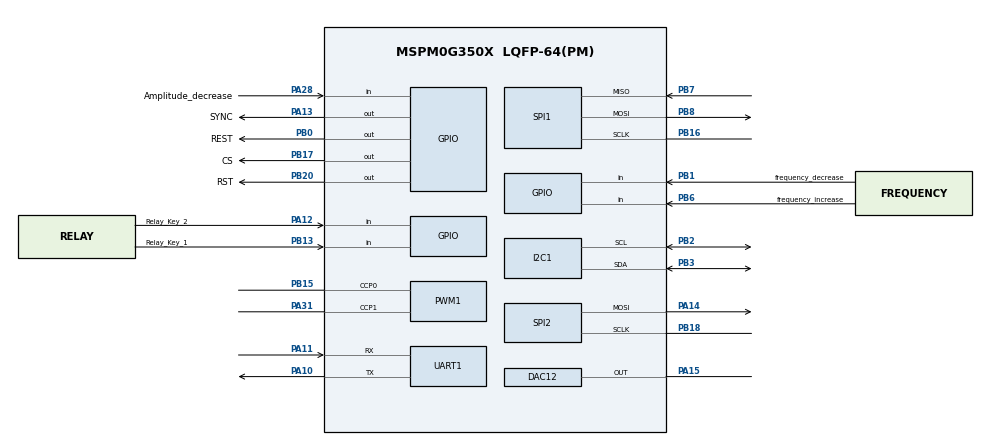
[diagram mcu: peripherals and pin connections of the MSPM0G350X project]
/**
 * @cliArgs --device "MSPM0G350X" --part "Default" --package "LQFP-64(PM)" --product "mspm0_sdk@2.04.00.06"
 * @versions {"tool":"1.24.0+4110"}
 */

/**
 * Import the modules used in this configuration.
 */
const DAC12         = scripting.addModule("/ti/driverlib/DAC12");
const GPIO          = scripting.addModule("/ti/driverlib/GPIO", {}, false);
const GPIO1         = GPIO.addInstance();
const GPIO2         = GPIO.addInstance();
const GPIO3         = GPIO.addInstance();
const GPIO4         = GPIO.addInstance();
const I2C           = scripting.addModule("/ti/driverlib/I2C", {}, false);
const I2C1          = I2C.addInstance();
const MATHACL       = scripting.addModule("/ti/driverlib/MATHACL");
const PWM           = scripting.addModule("/ti/driverlib/PWM", {}, false);
const PWM1          = PWM.addInstance();
const SPI           = scripting.addModule("/ti/driverlib/SPI", {}, false);
const SPI1          = SPI.addInstance();
const SPI2          = SPI.addInstance();
const SYSCTL        = scripting.addModule("/ti/driverlib/SYSCTL");
const SYSTICK       = scripting.addModule("/ti/driverlib/SYSTICK");
const UART          = scripting.addModule("/ti/driverlib/UART", {}, false);
const UART1         = UART.addInstance();
const ProjectConfig = scripting.addModule("/ti/project_config/ProjectConfig");

/**
 * Write custom configuration values to the imported modules.
 */
const divider6       = system.clockTree["PLL_CLK2X_DIV"];
divider6.divideValue = 4;

const divider7       = system.clockTree["PLL_PDIV"];
divider7.divideValue = 2;

const gate8  = system.clockTree["MFPCLKGATE"];
gate8.enable = true;

const multiplier2         = system.clockTree["PLL_QDIV"];
multiplier2.multiplyValue = 10;

const mux10       = system.clockTree["MFPCLKMUX"];
mux10.inputSelect = "MFPCLKMUX_HFCLK";

DAC12.dacOutputPinEn            = true;
DAC12.dacAmplifier              = "ON";
DAC12.dacSampleTimerEn          = true;
DAC12.dacNegVREF                = "VEREFN";
DAC12.peripheral.$assign        = "DAC0";
DAC12.peripheral.OutPin.$assign = "PA15";
DAC12.OutPinConfig.$name        = "ti_driverlib_gpio_GPIOPinGeneric5";
DAC12.OutPinConfig.enableConfig = true;

const Board = scripting.addModule("/ti/driverlib/Board", {}, false);

GPIO1.port                          = "PORTB";
GPIO1.$name                         = "GPIO_LEDS";
GPIO1.associatedPins.create(3);
GPIO1.associatedPins[0].$name       = "USER_LED_1";
GPIO1.associatedPins[0].assignedPin = "22";
GPIO1.associatedPins[1].$name       = "USER_LED_2";
GPIO1.associatedPins[1].assignedPin = "26";
GPIO1.associatedPins[2].$name       = "USER_LED_3";
GPIO1.associatedPins[2].assignedPin = "27";

GPIO2.$name                              = "AD7606";
GPIO2.port                               = "PORTB";
GPIO2.associatedPins.create(3);
GPIO2.associatedPins[0].internalResistor = "PULL_UP";
GPIO2.associatedPins[0].interruptEn      = true;
GPIO2.associatedPins[0].direction        = "INPUT";
GPIO2.associatedPins[0].$name            = "Busy";
GPIO2.associatedPins[0].polarity         = "FALL";
GPIO2.associatedPins[0].assignedPin      = "4";
GPIO2.associatedPins[1].$name            = "REST";
GPIO2.associatedPins[1].internalResistor = "PULL_UP";
GPIO2.associatedPins[1].pin.$assign      = "PB0";
GPIO2.associatedPins[2].$name            = "CS";
GPIO2.associatedPins[2].internalResistor = "PULL_UP";
GPIO2.associatedPins[2].pin.$assign      = "PB17";

GPIO3.$name                              = "AD9834";
GPIO3.associatedPins.create(2);
GPIO3.associatedPins[0].$name            = "SYNC";
GPIO3.associatedPins[0].internalResistor = "PULL_UP";
GPIO3.associatedPins[0].ioStructure      = "HS";
GPIO3.associatedPins[0].pin.$assign      = "PA13";
GPIO3.associatedPins[1].$name            = "RST";
GPIO3.associatedPins[1].internalResistor = "PULL_UP";
GPIO3.associatedPins[1].pin.$assign      = "PB20";

GPIO4.$name                              = "GPIO_SWITCHES";
GPIO4.associatedPins.create(6);
GPIO4.associatedPins[0].direction        = "INPUT";
GPIO4.associatedPins[0].internalResistor = "PULL_UP";
GPIO4.associatedPins[0].interruptEn      = true;
GPIO4.associatedPins[0].$name            = "frequency_increase";
GPIO4.associatedPins[0].polarity         = "RISE_FALL";
GPIO4.associatedPins[0].pin.$assign      = "PB6";
GPIO4.associatedPins[1].internalResistor = "PULL_UP";
GPIO4.associatedPins[1].direction        = "INPUT";
GPIO4.associatedPins[1].interruptEn      = true;
GPIO4.associatedPins[1].$name            = "frequency_decrease";
GPIO4.associatedPins[1].polarity         = "RISE_FALL";
GPIO4.associatedPins[1].pin.$assign      = "PB1";
GPIO4.associatedPins[2].initialValue     = "SET";
GPIO4.associatedPins[2].direction        = "INPUT";
GPIO4.associatedPins[2].polarity         = "RISE_FALL";
GPIO4.associatedPins[2].interruptEn      = true;
GPIO4.associatedPins[2].$name            = "Amplitude_increase";
GPIO4.associatedPins[3].$name            = "Amplitude_decrease";
GPIO4.associatedPins[3].initialValue     = "SET";
GPIO4.associatedPins[3].direction        = "INPUT";
GPIO4.associatedPins[3].interruptEn      = true;
GPIO4.associatedPins[3].polarity         = "RISE_FALL";
GPIO4.associatedPins[3].pin.$assign      = "PA28";
GPIO4.associatedPins[4].$name            = "Relay_Key_1";
GPIO4.associatedPins[4].direction        = "INPUT";
GPIO4.associatedPins[4].interruptEn      = true;
GPIO4.associatedPins[4].polarity         = "RISE_FALL";
GPIO4.associatedPins[4].pin.$assign      = "PB13";
GPIO4.associatedPins[5].$name            = "Relay_Key_2";
GPIO4.associatedPins[5].direction        = "INPUT";
GPIO4.associatedPins[5].interruptEn      = true;
GPIO4.associatedPins[5].polarity         = "RISE_FALL";
GPIO4.associatedPins[5].pin.$assign      = "PA12";

I2C1.basicEnableController             = true;
I2C1.basicControllerStandardBusSpeed   = "Fast";
I2C1.$name                             = "I2C_1";
I2C1.peripheral.$assign                = "I2C1";
I2C1.peripheral.sdaPin.$assign         = "PB3";
I2C1.peripheral.sclPin.$assign         = "PB2";
I2C1.sdaPinConfig.$name                = "ti_driverlib_gpio_GPIOPinGeneric0";
I2C1.sdaPinConfig.hideOutputInversion  = scripting.forceWrite(false);
I2C1.sdaPinConfig.onlyInternalResistor = scripting.forceWrite(false);
I2C1.sdaPinConfig.passedPeripheralType = scripting.forceWrite("Digital");
I2C1.sclPinConfig.$name                = "ti_driverlib_gpio_GPIOPinGeneric1";
I2C1.sclPinConfig.hideOutputInversion  = scripting.forceWrite(false);
I2C1.sclPinConfig.onlyInternalResistor = scripting.forceWrite(false);
I2C1.sclPinConfig.passedPeripheralType = scripting.forceWrite("Digital");

PWM1.$name                      = "PWM_0";
PWM1.pwmMode                    = "EDGE_ALIGN_UP";
PWM1.clockPrescale              = 25;
PWM1.timerCount                 = 125;
PWM1.peripheral.ccp0Pin.$assign = "PB15";
PWM1.peripheral.ccp1Pin.$assign = "PA31";
PWM1.PWM_CHANNEL_0.$name        = "ti_driverlib_pwm_PWMTimerCC0";
PWM1.PWM_CHANNEL_0.dutyCycle    = 50;
PWM1.PWM_CHANNEL_1.$name        = "ti_driverlib_pwm_PWMTimerCC1";
PWM1.PWM_CHANNEL_1.dutyCycle    = 90;
PWM1.ccp0PinConfig.$name        = "ti_driverlib_gpio_GPIOPinGeneric8";
PWM1.ccp1PinConfig.$name        = "ti_driverlib_gpio_GPIOPinGeneric9";

SPI1.$name                          = "SPI_0";
SPI1.enabledDMAEvent1Triggers       = "DL_SPI_DMA_INTERRUPT_RX";
SPI1.enabledInterrupts              = ["DMA_DONE_RX"];
SPI1.targetBitRate                  = 16000000;
SPI1.txFifoThreshold                = "DL_SPI_TX_FIFO_LEVEL_EMPTY";
SPI1.dataSize                       = 16;
SPI1.rxFifoThreshold                = "DL_SPI_RX_FIFO_LEVEL_1_4_FULL";
SPI1.enabledDMAEvent2Triggers       = "DL_SPI_DMA_INTERRUPT_TX";
SPI1.frameFormat                    = "MOTO3";
SPI1.sclkPinConfig.$name            = "ti_driverlib_gpio_GPIOPinGeneric2";
SPI1.mosiPinConfig.$name            = "ti_driverlib_gpio_GPIOPinGeneric3";
SPI1.misoPinConfig.$name            = "ti_driverlib_gpio_GPIOPinGeneric4";
SPI1.DMA_CHANNEL_EVENT1.$name       = "DMA_CH0";
SPI1.DMA_CHANNEL_EVENT1.addressMode = "f2b";
SPI1.DMA_CHANNEL_EVENT1.srcLength   = "HALF_WORD";
SPI1.DMA_CHANNEL_EVENT1.dstLength   = "HALF_WORD";
SPI1.DMA_CHANNEL_EVENT2.$name       = "DMA_CH1";
SPI1.peripheral.$assign             = "SPI1";
SPI1.peripheral.sclkPin.$assign     = "PB16";
SPI1.peripheral.mosiPin.$assign     = "PB8";
SPI1.peripheral.misoPin.$assign     = "PB7";

SPI2.$name                          = "SPI_1";
SPI2.dataSize                       = 16;
SPI2.frameFormat                    = "MOTO3";
SPI2.targetBitRate                  = 16000000;
SPI2.polarity                       = "1";
SPI2.sclkPinConfig.$name            = "ti_driverlib_gpio_GPIOPinGeneric10";
SPI2.sclkPinConfig.internalResistor = "PULL_UP";
SPI2.mosiPinConfig.$name            = "ti_driverlib_gpio_GPIOPinGeneric11";
SPI2.misoPinConfig.$name            = "ti_driverlib_gpio_GPIOPinGeneric12";
SPI2.peripheral.$assign             = "SPI0";
SPI2.peripheral.sclkPin.$assign     = "PB18";
SPI2.peripheral.mosiPin.$assign     = "PA14";

SYSCTL.MFPCLKEn              = true;
SYSCTL.MFCLKEn               = true;
SYSCTL.forceDefaultClkConfig = true;
SYSCTL.validateClkStatus     = true;

UART1.$name                    = "UART_0";
UART1.targetBaudRate           = 115200;
UART1.enabledInterrupts        = ["RX"];
UART1.peripheral.$assign       = "UART0";
UART1.peripheral.rxPin.$assign = "PA11";
UART1.peripheral.txPin.$assign = "PA10";
UART1.txPinConfig.$name        = "ti_driverlib_gpio_GPIOPinGeneric6";
UART1.rxPinConfig.$name        = "ti_driverlib_gpio_GPIOPinGeneric7";

const VREF                  = scripting.addModule("/ti/driverlib/VREF", {}, false);
VREF.vrefPosPinConfig.$name = "ti_driverlib_gpio_GPIOPinGeneric13";

ProjectConfig.genLibCMSIS     = true;
ProjectConfig.genLibIQ        = true;
ProjectConfig.genLibIQVersion = "MATHACL";

/**
 * Pinmux solution for unlocked pins/peripherals. This ensures that minor changes to the automatic solver in a future
 * version of the tool will not impact the pinmux you originally saw.  These lines can be completely deleted in order to
 * re-solve from scratch.
 */
Board.peripheral.$suggestSolution                   = "DEBUGSS";
Board.peripheral.swclkPin.$suggestSolution          = "PA20";
Board.peripheral.swdioPin.$suggestSolution          = "PA19";
GPIO1.associatedPins[0].pin.$suggestSolution        = "PB22";
GPIO1.associatedPins[1].pin.$suggestSolution        = "PB26";
GPIO1.associatedPins[2].pin.$suggestSolution        = "PB27";
GPIO2.associatedPins[0].pin.$suggestSolution        = "PB4";
GPIO4.associatedPins[2].pin.$suggestSolution        = "PB14";
PWM1.peripheral.$suggestSolution                    = "TIMG7";
SPI1.DMA_CHANNEL_EVENT1.peripheral.$suggestSolution = "DMA_CH1";
SPI1.DMA_CHANNEL_EVENT2.peripheral.$suggestSolution = "DMA_CH0";
SPI2.peripheral.misoPin.$suggestSolution            = "PA4";
SYSCTL.peripheral.$suggestSolution                  = "SYSCTL";
VREF.peripheral.$suggestSolution                    = "VREF";
VREF.peripheral.vrefPosPin.$suggestSolution         = "PA23";
